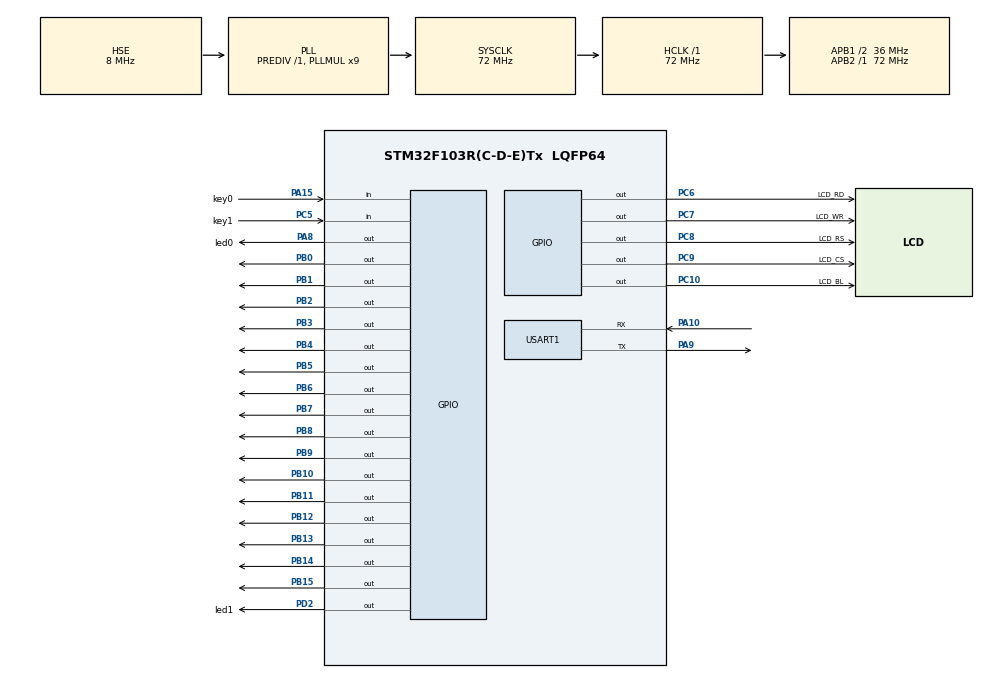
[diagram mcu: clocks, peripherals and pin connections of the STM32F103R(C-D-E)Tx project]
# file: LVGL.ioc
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Dma.Request0=USART1_RX
Dma.Request1=USART1_TX
Dma.USART1_RX.0.Direction=DMA_PERIPH_TO_MEMORY
Dma.USART1_RX.0.Instance=DMA1_Channel5
Dma.USART1_RX.0.MemDataAlignment=DMA_MDATAALIGN_BYTE
Dma.USART1_RX.0.MemInc=DMA_MINC_ENABLE
Dma.USART1_RX.0.Mode=DMA_NORMAL
Dma.USART1_RX.0.PeriphDataAlignment=DMA_PDATAALIGN_BYTE
Dma.USART1_RX.0.PeriphInc=DMA_PINC_DISABLE
Dma.USART1_RX.0.Priority=DMA_PRIORITY_LOW
Dma.USART1_TX.1.Direction=DMA_MEMORY_TO_PERIPH
Dma.USART1_TX.1.Instance=DMA1_Channel4
Dma.USART1_TX.1.MemDataAlignment=DMA_MDATAALIGN_BYTE
Dma.USART1_TX.1.MemInc=DMA_MINC_ENABLE
Dma.USART1_TX.1.Mode=DMA_NORMAL
Dma.USART1_TX.1.PeriphDataAlignment=DMA_PDATAALIGN_BYTE
Dma.USART1_TX.1.PeriphInc=DMA_PINC_DISABLE
Dma.USART1_TX.1.Priority=DMA_PRIORITY_LOW
Mcu.Family=STM32F1
Mcu.Name=STM32F103R(C-D-E)Tx
Mcu.Package=LQFP64
NVIC.DMA1_Channel4_IRQn=true\:0\:0\:false\:false\:true\:false\:true\:true
NVIC.DMA1_Channel5_IRQn=true\:0\:0\:false\:false\:true\:false\:true\:true
NVIC.PriorityGroup=NVIC_PRIORITYGROUP_4
NVIC.TIM6_IRQn=true\:0\:0\:false\:false\:true\:true\:true\:true
NVIC.USART1_IRQn=true\:1\:0\:true\:false\:true\:true\:true\:true
PA10.Mode=Asynchronous
PA10.Signal=USART1_RX
PA13.Mode=Serial_Wire
PA13.Signal=SYS_JTMS-SWDIO
PA14.Mode=Serial_Wire
PA14.Signal=SYS_JTCK-SWCLK
PA15.GPIO_Label=key0
PA15.GPIO_PuPd=GPIO_NOPULL
PA15.Signal=GPIO_Input
PA8.GPIO_Label=led0
PA8.GPIO_PuPd=GPIO_PULLUP
PA8.GPIO_Speed=GPIO_SPEED_FREQ_MEDIUM
PA8.Signal=GPIO_Output
PA9.Mode=Asynchronous
PA9.Signal=USART1_TX
PB0.Signal=GPIO_Output
PB1.GPIO_PuPd=GPIO_PULLUP
PB1.GPIO_Speed=GPIO_SPEED_FREQ_HIGH
PB1.Signal=GPIO_Output
PB10.GPIO_PuPd=GPIO_PULLUP
PB10.GPIO_Speed=GPIO_SPEED_FREQ_HIGH
PB10.Signal=GPIO_Output
PB11.GPIO_PuPd=GPIO_PULLUP
PB11.GPIO_Speed=GPIO_SPEED_FREQ_HIGH
PB11.Signal=GPIO_Output
PB12.GPIO_PuPd=GPIO_PULLUP
PB12.GPIO_Speed=GPIO_SPEED_FREQ_HIGH
PB12.Signal=GPIO_Output
PB13.GPIO_PuPd=GPIO_PULLUP
PB13.GPIO_Speed=GPIO_SPEED_FREQ_HIGH
PB13.Signal=GPIO_Output
PB14.GPIO_PuPd=GPIO_PULLUP
PB14.GPIO_Speed=GPIO_SPEED_FREQ_HIGH
PB14.Signal=GPIO_Output
PB15.GPIO_PuPd=GPIO_PULLUP
PB15.GPIO_Speed=GPIO_SPEED_FREQ_HIGH
PB15.Signal=GPIO_Output
PB2.GPIO_PuPd=GPIO_PULLUP
PB2.GPIO_Speed=GPIO_SPEED_FREQ_HIGH
PB2.Signal=GPIO_Output
PB3.GPIO_PuPd=GPIO_PULLUP
PB3.GPIO_Speed=GPIO_SPEED_FREQ_HIGH
PB3.Signal=GPIO_Output
PB4.GPIO_PuPd=GPIO_PULLUP
PB4.GPIO_Speed=GPIO_SPEED_FREQ_HIGH
PB4.Signal=GPIO_Output
PB5.GPIO_PuPd=GPIO_PULLUP
PB5.GPIO_Speed=GPIO_SPEED_FREQ_HIGH
PB5.Signal=GPIO_Output
PB6.GPIO_PuPd=GPIO_PULLUP
PB6.GPIO_Speed=GPIO_SPEED_FREQ_HIGH
PB6.Signal=GPIO_Output
PB7.GPIO_PuPd=GPIO_PULLUP
PB7.GPIO_Speed=GPIO_SPEED_FREQ_HIGH
PB7.Signal=GPIO_Output
PB8.GPIO_PuPd=GPIO_PULLDOWN
PB8.GPIO_Speed=GPIO_SPEED_FREQ_HIGH
PB8.Signal=GPIO_Output
PB9.GPIO_PuPd=GPIO_PULLUP
PB9.GPIO_Speed=GPIO_SPEED_FREQ_HIGH
PB9.Signal=GPIO_Output
PC10.GPIO_Label=LCD_BL
PC10.GPIO_PuPd=GPIO_PULLUP
PC10.GPIO_Speed=GPIO_SPEED_FREQ_HIGH
PC10.Signal=GPIO_Output
PC14-OSC32_IN.Mode=LSE-External-Oscillator
PC14-OSC32_IN.Signal=RCC_OSC32_IN
PC15-OSC32_OUT.Mode=LSE-External-Oscillator
PC15-OSC32_OUT.Signal=RCC_OSC32_OUT
PC5.GPIO_Label=key1
PC5.GPIO_PuPd=GPIO_NOPULL
PC5.Signal=GPIO_Input
PC6.GPIO_Label=LCD_RD
PC6.GPIO_PuPd=GPIO_PULLUP
PC6.GPIO_Speed=GPIO_SPEED_FREQ_HIGH
PC6.Signal=GPIO_Output
PC7.GPIO_Label=LCD_WR
PC7.GPIO_PuPd=GPIO_PULLUP
PC7.GPIO_Speed=GPIO_SPEED_FREQ_HIGH
PC7.Signal=GPIO_Output
PC8.GPIO_Label=LCD_RS
PC8.GPIO_PuPd=GPIO_PULLUP
PC8.GPIO_Speed=GPIO_SPEED_FREQ_HIGH
PC8.Signal=GPIO_Output
PC9.GPIO_Label=LCD_CS
PC9.GPIO_PuPd=GPIO_PULLUP
PC9.GPIO_Speed=GPIO_SPEED_FREQ_HIGH
PC9.Signal=GPIO_Output
PD0-OSC_IN.Mode=HSE-External-Oscillator
PD0-OSC_IN.Signal=RCC_OSC_IN
PD1-OSC_OUT.Mode=HSE-External-Oscillator
PD1-OSC_OUT.Signal=RCC_OSC_OUT
PD2.GPIO_Label=led1
PD2.GPIO_PuPd=GPIO_PULLUP
PD2.GPIO_Speed=GPIO_SPEED_FREQ_MEDIUM
PD2.Signal=GPIO_Output
ProjectManager.HeapSize=0x200
ProjectManager.StackSize=0x400
ProjectManager.TargetToolchain=MDK-ARM V5.32
RCC.AHBFreq_Value=72000000
RCC.APB1CLKDivider=RCC_HCLK_DIV2
RCC.APB1Freq_Value=36000000
RCC.APB1TimFreq_Value=72000000
RCC.APB2Freq_Value=72000000
RCC.APB2TimFreq_Value=72000000
RCC.HCLKFreq_Value=72000000
RCC.PLLMUL=RCC_PLL_MUL9
RCC.PLLSourceVirtual=RCC_PLLSOURCE_HSE
RCC.SYSCLKFreq_VALUE=72000000
RCC.SYSCLKSource=RCC_SYSCLKSOURCE_PLLCLK
RCC.USBFreq_Value=72000000
TIM6.Period=7199
TIM6.Prescaler=9
USART1.VirtualMode=VM_ASYNC
VP_TIM6_VS_ClockSourceINT.Mode=Enable_Timer
board=custom

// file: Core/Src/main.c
/* USER CODE BEGIN Header */
/**
  ******************************************************************************
  * @file           : main.c
  * @brief          : Main program body
  ******************************************************************************
  * @attention
  *
  * Copyright (c) 2022 STMicroelectronics.
  * All rights reserved.
  *
  * This software is licensed under terms that can be found in the LICENSE file
  * in the root directory of this software component.
  * If no LICENSE file comes with this software, it is provided AS-IS.
  *
  ******************************************************************************
  */
/* USER CODE END Header */
#include "main.h"
#include "dma.h"
#include "tim.h"
#include "usart.h"
#include "gpio.h"

/* USER CODE BEGIN Includes */
#include "key_led.h"
#include "lcd.h"
#include "stdio.h"
#include "lv_port_disp_template.h"
//#include "lv_port_indev_template.h"
//#include "touch.h"
/* USER CODE END Includes */

/* USER CODE BEGIN PV */
//uint8_t Recceive_buffer[8]="";//定义接收数组,6为字符大小上限
//uint8_t lcd_id[12];						//存放LCD ID字符串
//char Output_buffer[16];						//存放输出LCD ID字符串
/* USER CODE END PV */

void SystemClock_Config(void);

/* USER CODE BEGIN 0 */
//串口接收回调函数
// void HAL_UART_RxCpltCallback(UART_HandleTypeDef *huart){
//   HAL_UART_Transmit_DMA(&huart1,Recceive_buffer,8);
//   HAL_UART_Receive_DMA(&huart1,Recceive_buffer,8);
// }

/* USER CODE END 0 */

int main(void)
{

  /* MCU Configuration--------------------------------------------------------*/

  /* Reset of all peripherals, Initializes the Flash interface and the Systick. */
  HAL_Init();

  /* Configure the system clock */
  SystemClock_Config();

  /* Initialize all configured peripherals */
  MX_GPIO_Init();
  MX_DMA_Init();
  MX_USART1_UART_Init();
  MX_TIM6_Init();
  /* USER CODE BEGIN 2 */
  __HAL_UART_ENABLE_IT(&huart1,UART_IT_IDLE);//串口空闲中断启用
	lv_init();
	lv_port_disp_init();

		lv_obj_t* switch_obj = lv_switch_create(lv_scr_act());
    lv_obj_set_size(switch_obj, 120, 60);
    lv_obj_align(switch_obj, LV_ALIGN_CENTER, 0, 0);

  /* USER CODE END 2 */

  /* Infinite loop */
  while (1)
  {

    /* USER CODE BEGIN 3 */

		HAL_Delay(5);
		lv_timer_handler();
  }
  /* USER CODE END 3 */
}

void SystemClock_Config(void)
{
  RCC_OscInitTypeDef RCC_OscInitStruct = {0};
  RCC_ClkInitTypeDef RCC_ClkInitStruct = {0};

  /** Initializes the RCC Oscillators according to the specified parameters
  * in the RCC_OscInitTypeDef structure.
  */
  RCC_OscInitStruct.OscillatorType = RCC_OSCILLATORTYPE_HSE;
  RCC_OscInitStruct.HSEState = RCC_HSE_ON;
  RCC_OscInitStruct.HSEPredivValue = RCC_HSE_PREDIV_DIV1;
  RCC_OscInitStruct.HSIState = RCC_HSI_ON;
  RCC_OscInitStruct.PLL.PLLState = RCC_PLL_ON;
  RCC_OscInitStruct.PLL.PLLSource = RCC_PLLSOURCE_HSE;
  RCC_OscInitStruct.PLL.PLLMUL = RCC_PLL_MUL9;
  if (HAL_RCC_OscConfig(&RCC_OscInitStruct) != HAL_OK)
  {
    Error_Handler();
  }

  /** Initializes the CPU, AHB and APB buses clocks
  */
  RCC_ClkInitStruct.ClockType = RCC_CLOCKTYPE_HCLK|RCC_CLOCKTYPE_SYSCLK
                              |RCC_CLOCKTYPE_PCLK1|RCC_CLOCKTYPE_PCLK2;
  RCC_ClkInitStruct.SYSCLKSource = RCC_SYSCLKSOURCE_PLLCLK;
  RCC_ClkInitStruct.AHBCLKDivider = RCC_SYSCLK_DIV1;
  RCC_ClkInitStruct.APB1CLKDivider = RCC_HCLK_DIV2;
  RCC_ClkInitStruct.APB2CLKDivider = RCC_HCLK_DIV1;

  if (HAL_RCC_ClockConfig(&RCC_ClkInitStruct, FLASH_LATENCY_2) != HAL_OK)
  {
    Error_Handler();
  }
}

void Error_Handler(void)
{
  __disable_irq();
  while (1)
  {
  }
}
